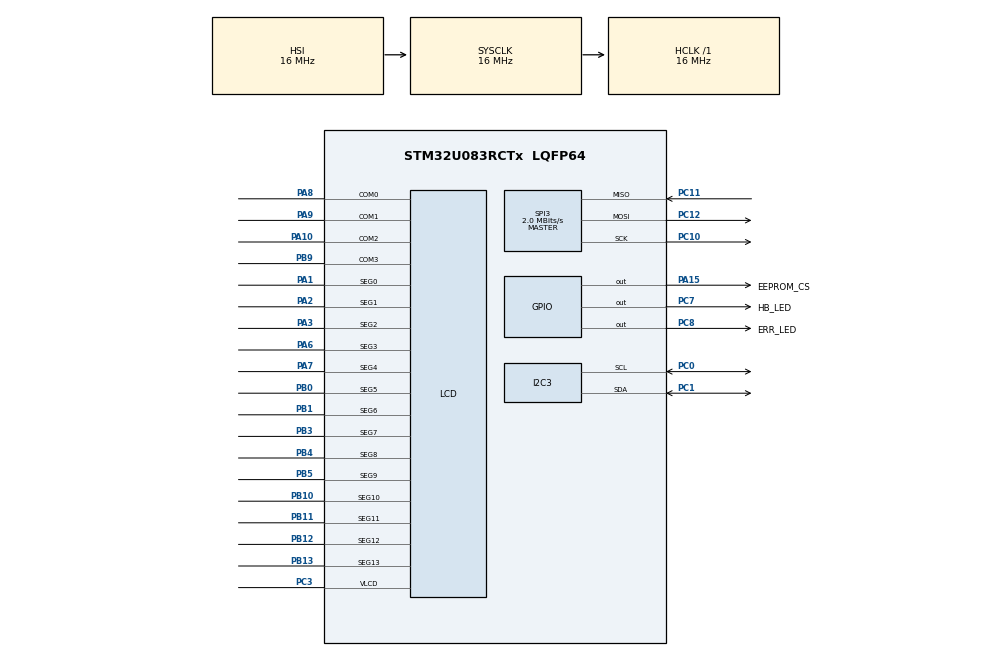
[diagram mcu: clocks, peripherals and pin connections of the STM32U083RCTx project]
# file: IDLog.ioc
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ADC1.Channel-0\#ChannelRegularConversion=ADC_CHANNEL_VBAT
ADC1.ClockPrescaler=ADC_CLOCK_ASYNC_DIV1
ADC1.ContinuousConvMode=ENABLE
ADC1.NbrOfConversionFlag=1
ADC1.Rank-0\#ChannelRegularConversion=1
ADC1.RankArg-0\#ChannelRegularConversion=ADC_REGULAR_RANK_1
ADC1.SamplingTime-0\#ChannelRegularConversion=ADC_SAMPLINGTIME_COMMON_1
ADC1.SamplingTimeCommon1=ADC_SAMPLETIME_79CYCLES_5
ADC1.SelectedChannel=ADC_CHANNEL_VBAT
ADC1.master=1
I2C3.Timing=0x00303D5B
LCD.Contrast=LCD_CONTRASTLEVEL_7
LCD.Divider=LCD_DIVIDER_31
LCD.Prescaler=LCD_PRESCALER_2
LCD.PulseOnDuration=LCD_PULSEONDURATION_5
Mcu.Family=STM32U0
Mcu.Name=STM32U083RCTx
Mcu.Package=LQFP64
NVIC.PriorityGroup=NVIC_PRIORITYGROUP_2
NVIC.TIM16_IRQn=true\:0\:0\:false\:false\:true\:true\:true\:true
PA1.Mode=SEG0
PA1.Signal=LCD_SEG0
PA10.Mode=1/4 Duty Cycle
PA10.Signal=LCD_COM2
PA15.GPIO_Label=EEPROM_CS
PA15.Signal=GPIO_Output
PA2.Mode=SEG1
PA2.Signal=LCD_SEG1
PA3.Mode=SEG2
PA3.Signal=LCD_SEG2
PA6.Mode=SEG3
PA6.Signal=LCD_SEG3
PA7.Mode=SEG4
PA7.Signal=LCD_SEG4
PA8.Mode=1/4 Duty Cycle
PA8.Signal=LCD_COM0
PA9.Mode=1/4 Duty Cycle
PA9.Signal=LCD_COM1
PB0.Mode=SEG5
PB0.Signal=LCD_SEG5
PB1.Mode=SEG6
PB1.Signal=LCD_SEG6
PB10.Mode=SEG10
PB10.Signal=LCD_SEG10
PB11.Mode=SEG11
PB11.Signal=LCD_SEG11
PB12.Mode=SEG12
PB12.Signal=LCD_SEG12
PB13.Mode=SEG13
PB13.Signal=LCD_SEG13
PB3.Mode=SEG7
PB3.Signal=LCD_SEG7
PB4.Mode=SEG8
PB4.Signal=LCD_SEG8
PB5.Mode=SEG9
PB5.Signal=LCD_SEG9
PB9.Mode=1/4 Duty Cycle
PB9.Signal=LCD_COM3
PC0.Mode=I2C
PC0.Signal=I2C3_SCL
PC1.Mode=I2C
PC1.Signal=I2C3_SDA
PC10.Mode=Full_Duplex_Master
PC10.Signal=SPI3_SCK
PC11.Mode=Full_Duplex_Master
PC11.Signal=SPI3_MISO
PC12.Mode=Full_Duplex_Master
PC12.Signal=SPI3_MOSI
PC3.Mode=1/4 Duty Cycle
PC3.Signal=LCD_VLCD
PC7.GPIO_Label=HB_LED
PC7.Signal=GPIO_Output
PC8.GPIO_Label=ERR_LED
PC8.Signal=GPIO_Output
ProjectManager.HeapSize=0x200
ProjectManager.StackSize=0x400
ProjectManager.TargetToolchain=STM32CubeIDE
RCC.AHBFreq_Value=16000000
RCC.CortexFreq_Value=16000000
RCC.HCLKFreq_Value=16000000
RCC.HSE_VALUE=4000000
RCC.HSI48_VALUE=48000000
RCC.HSI_VALUE=16000000
RCC.LSE_VALUE=32768
RCC.MSI_VALUE=4000000
RCC.SYSCLKFreq_VALUE=16000000
RCC.VCOOutputFreq_Value=64000000
RTC.Year=25
SPI3.BaudRatePrescaler=SPI_BAUDRATEPRESCALER_8
SPI3.CalculateBaudRate=2.0 MBits/s
SPI3.DataSize=SPI_DATASIZE_8BIT
SPI3.Direction=SPI_DIRECTION_2LINES
SPI3.Mode=SPI_MODE_MASTER
SPI3.VirtualType=VM_MASTER
TIM16.AutoReloadPreload=TIM_AUTORELOAD_PRELOAD_ENABLE
TIM16.Period=1000
TIM16.Prescaler=15
VP_ADC1_Vbat_Input.Mode=IN-Vbat
VP_PWR_VS_SECSignals.Mode=Security/Privilege
VP_RTC_VS_RTC_Activate.Mode=RTC_Enabled
VP_RTC_VS_RTC_Calendar.Mode=RTC_Calendar
VP_TIM16_VS_ClockSourceINT.Mode=Enable_Timer
board=custom

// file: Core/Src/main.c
/* USER CODE BEGIN Header */
/**
  ******************************************************************************
  * @file           : main.c
  * @brief          : Main program body
  ******************************************************************************
  * @attention
  *
  * Copyright (c) 2025 STMicroelectronics.
  * All rights reserved.
  *
  * This software is licensed under terms that can be found in the LICENSE file
  * in the root directory of this software component.
  * If no LICENSE file comes with this software, it is provided AS-IS.
  *
  ******************************************************************************
  */
/* USER CODE END Header */
#include "main.h"

/* USER CODE BEGIN Includes */
#include "HardwareConfig.h"
/* USER CODE END Includes */

ADC_HandleTypeDef hadc1;

I2C_HandleTypeDef hi2c3;

LCD_HandleTypeDef hlcd;

RTC_HandleTypeDef hrtc;

SPI_HandleTypeDef hspi3;

TIM_HandleTypeDef htim16;

void SystemClock_Config(void);
static void MX_GPIO_Init(void);
static void MX_I2C3_Init(void);
static void MX_SPI3_Init(void);
static void MX_ADC1_Init(void);
static void MX_TIM16_Init(void);
static void MX_LCD_Init(void);
static void MX_RTC_Init(void);

int main(void)
{

  /* MCU Configuration--------------------------------------------------------*/

  /* Reset of all peripherals, Initializes the Flash interface and the Systick. */
  HAL_Init();

  /* Configure the system clock */
  SystemClock_Config();

  /* Initialize all configured peripherals */
  MX_GPIO_Init();
  MX_I2C3_Init();
  MX_SPI3_Init();
  MX_ADC1_Init();
  MX_TIM16_Init();
  MX_LCD_Init();
  MX_RTC_Init();
  /* USER CODE BEGIN 2 */
  MainAppInit();
  /* USER CODE END 2 */

  /* Infinite loop */
  while (1)
  {

    /* USER CODE BEGIN 3 */
	  MainAppWhileFunction();
  }
  /* USER CODE END 3 */
}

void SystemClock_Config(void)
{
  RCC_OscInitTypeDef RCC_OscInitStruct = {0};
  RCC_ClkInitTypeDef RCC_ClkInitStruct = {0};

  /** Configure the main internal regulator output voltage
  */
  HAL_PWREx_ControlVoltageScaling(PWR_REGULATOR_VOLTAGE_SCALE2);

  /** Initializes the RCC Oscillators according to the specified parameters
  * in the RCC_OscInitTypeDef structure.
  */
  RCC_OscInitStruct.OscillatorType = RCC_OSCILLATORTYPE_HSI|RCC_OSCILLATORTYPE_LSI;
  RCC_OscInitStruct.HSIState = RCC_HSI_ON;
  RCC_OscInitStruct.HSICalibrationValue = RCC_HSICALIBRATION_DEFAULT;
  RCC_OscInitStruct.LSIState = RCC_LSI_ON;
  RCC_OscInitStruct.PLL.PLLState = RCC_PLL_NONE;
  if (HAL_RCC_OscConfig(&RCC_OscInitStruct) != HAL_OK)
  {
    Error_Handler();
  }

  /** Initializes the CPU, AHB and APB buses clocks
  */
  RCC_ClkInitStruct.ClockType = RCC_CLOCKTYPE_HCLK|RCC_CLOCKTYPE_SYSCLK
                              |RCC_CLOCKTYPE_PCLK1;
  RCC_ClkInitStruct.SYSCLKSource = RCC_SYSCLKSOURCE_HSI;
  RCC_ClkInitStruct.AHBCLKDivider = RCC_SYSCLK_DIV1;
  RCC_ClkInitStruct.APB1CLKDivider = RCC_HCLK_DIV1;

  if (HAL_RCC_ClockConfig(&RCC_ClkInitStruct, FLASH_LATENCY_1) != HAL_OK)
  {
    Error_Handler();
  }
}

static void MX_ADC1_Init(void)
{

  ADC_ChannelConfTypeDef sConfig = {0};

  /** Configure the global features of the ADC (Clock, Resolution, Data Alignment and number of conversion)
  */
  hadc1.Instance = ADC1;
  hadc1.Init.ClockPrescaler = ADC_CLOCK_ASYNC_DIV1;
  hadc1.Init.Resolution = ADC_RESOLUTION_12B;
  hadc1.Init.DataAlign = ADC_DATAALIGN_RIGHT;
  hadc1.Init.ScanConvMode = ADC_SCAN_DISABLE;
  hadc1.Init.EOCSelection = ADC_EOC_SINGLE_CONV;
  hadc1.Init.LowPowerAutoWait = DISABLE;
  hadc1.Init.LowPowerAutoPowerOff = DISABLE;
  hadc1.Init.ContinuousConvMode = ENABLE;
  hadc1.Init.NbrOfConversion = 1;
  hadc1.Init.ExternalTrigConv = ADC_SOFTWARE_START;
  hadc1.Init.ExternalTrigConvEdge = ADC_EXTERNALTRIGCONVEDGE_NONE;
  hadc1.Init.DMAContinuousRequests = DISABLE;
  hadc1.Init.Overrun = ADC_OVR_DATA_PRESERVED;
  hadc1.Init.SamplingTimeCommon1 = ADC_SAMPLETIME_79CYCLES_5;
  hadc1.Init.SamplingTimeCommon2 = ADC_SAMPLETIME_1CYCLE_5;
  hadc1.Init.OversamplingMode = DISABLE;
  hadc1.Init.TriggerFrequencyMode = ADC_TRIGGER_FREQ_HIGH;
  if (HAL_ADC_Init(&hadc1) != HAL_OK)
  {
    Error_Handler();
  }

  /** Configure Regular Channel
  */
  sConfig.Channel = ADC_CHANNEL_VBAT;
  sConfig.Rank = ADC_REGULAR_RANK_1;
  sConfig.SamplingTime = ADC_SAMPLINGTIME_COMMON_1;
  if (HAL_ADC_ConfigChannel(&hadc1, &sConfig) != HAL_OK)
  {
    Error_Handler();
  }

}

static void MX_I2C3_Init(void)
{

  hi2c3.Instance = I2C3;
  hi2c3.Init.Timing = 0x00303D5B;
  hi2c3.Init.OwnAddress1 = 0;
  hi2c3.Init.AddressingMode = I2C_ADDRESSINGMODE_7BIT;
  hi2c3.Init.DualAddressMode = I2C_DUALADDRESS_DISABLE;
  hi2c3.Init.OwnAddress2 = 0;
  hi2c3.Init.OwnAddress2Masks = I2C_OA2_NOMASK;
  hi2c3.Init.GeneralCallMode = I2C_GENERALCALL_DISABLE;
  hi2c3.Init.NoStretchMode = I2C_NOSTRETCH_DISABLE;
  if (HAL_I2C_Init(&hi2c3) != HAL_OK)
  {
    Error_Handler();
  }

  /** Configure Analogue filter
  */
  if (HAL_I2CEx_ConfigAnalogFilter(&hi2c3, I2C_ANALOGFILTER_ENABLE) != HAL_OK)
  {
    Error_Handler();
  }

  /** Configure Digital filter
  */
  if (HAL_I2CEx_ConfigDigitalFilter(&hi2c3, 0) != HAL_OK)
  {
    Error_Handler();
  }

}

static void MX_LCD_Init(void)
{

  hlcd.Instance = LCD;
  hlcd.Init.Prescaler = LCD_PRESCALER_2;
  hlcd.Init.Divider = LCD_DIVIDER_31;
  hlcd.Init.Duty = LCD_DUTY_1_4;
  hlcd.Init.Bias = LCD_BIAS_1_4;
  hlcd.Init.VoltageSource = LCD_VOLTAGESOURCE_INTERNAL;
  hlcd.Init.Contrast = LCD_CONTRASTLEVEL_7;
  hlcd.Init.DeadTime = LCD_DEADTIME_0;
  hlcd.Init.PulseOnDuration = LCD_PULSEONDURATION_5;
  hlcd.Init.BlinkMode = LCD_BLINKMODE_OFF;
  hlcd.Init.BlinkFrequency = LCD_BLINKFREQUENCY_DIV8;
  hlcd.Init.MuxSegment = LCD_MUXSEGMENT_DISABLE;
  if (HAL_LCD_Init(&hlcd) != HAL_OK)
  {
    Error_Handler();
  }

}

static void MX_RTC_Init(void)
{

  RTC_TimeTypeDef sTime = {0};
  RTC_DateTypeDef sDate = {0};

  /** Initialize RTC Only
  */
  hrtc.Instance = RTC;
  hrtc.Init.HourFormat = RTC_HOURFORMAT_24;
  hrtc.Init.AsynchPrediv = 127;
  hrtc.Init.SynchPrediv = 255;
  hrtc.Init.OutPut = RTC_OUTPUT_DISABLE;
  hrtc.Init.OutPutRemap = RTC_OUTPUT_REMAP_NONE;
  hrtc.Init.OutPutPolarity = RTC_OUTPUT_POLARITY_HIGH;
  hrtc.Init.OutPutType = RTC_OUTPUT_TYPE_OPENDRAIN;
  hrtc.Init.OutPutPullUp = RTC_OUTPUT_PULLUP_NONE;
  hrtc.Init.BinMode = RTC_BINARY_NONE;
  if (HAL_RTC_Init(&hrtc) != HAL_OK)
  {
    Error_Handler();
  }

  /** Initialize RTC and set the Time and Date
  */
  sTime.Hours = 0x0;
  sTime.Minutes = 0x0;
  sTime.Seconds = 0x0;
  sTime.DayLightSaving = RTC_DAYLIGHTSAVING_NONE;
  sTime.StoreOperation = RTC_STOREOPERATION_RESET;
  if (HAL_RTC_SetTime(&hrtc, &sTime, RTC_FORMAT_BCD) != HAL_OK)
  {
    Error_Handler();
  }
  sDate.WeekDay = RTC_WEEKDAY_MONDAY;
  sDate.Month = RTC_MONTH_JANUARY;
  sDate.Date = 0x1;
  sDate.Year = 0x25;

  if (HAL_RTC_SetDate(&hrtc, &sDate, RTC_FORMAT_BCD) != HAL_OK)
  {
    Error_Handler();
  }

}

static void MX_SPI3_Init(void)
{

  /* SPI3 parameter configuration*/
  hspi3.Instance = SPI3;
  hspi3.Init.Mode = SPI_MODE_MASTER;
  hspi3.Init.Direction = SPI_DIRECTION_2LINES;
  hspi3.Init.DataSize = SPI_DATASIZE_8BIT;
  hspi3.Init.CLKPolarity = SPI_POLARITY_LOW;
  hspi3.Init.CLKPhase = SPI_PHASE_1EDGE;
  hspi3.Init.NSS = SPI_NSS_SOFT;
  hspi3.Init.BaudRatePrescaler = SPI_BAUDRATEPRESCALER_8;
  hspi3.Init.FirstBit = SPI_FIRSTBIT_MSB;
  hspi3.Init.TIMode = SPI_TIMODE_DISABLE;
  hspi3.Init.CRCCalculation = SPI_CRCCALCULATION_DISABLE;
  hspi3.Init.CRCPolynomial = 7;
  hspi3.Init.CRCLength = SPI_CRC_LENGTH_DATASIZE;
  hspi3.Init.NSSPMode = SPI_NSS_PULSE_ENABLE;
  if (HAL_SPI_Init(&hspi3) != HAL_OK)
  {
    Error_Handler();
  }

}

static void MX_TIM16_Init(void)
{

  htim16.Instance = TIM16;
  htim16.Init.Prescaler = 15;
  htim16.Init.CounterMode = TIM_COUNTERMODE_UP;
  htim16.Init.Period = 1000;
  htim16.Init.ClockDivision = TIM_CLOCKDIVISION_DIV1;
  htim16.Init.RepetitionCounter = 0;
  htim16.Init.AutoReloadPreload = TIM_AUTORELOAD_PRELOAD_ENABLE;
  if (HAL_TIM_Base_Init(&htim16) != HAL_OK)
  {
    Error_Handler();
  }

}

static void MX_GPIO_Init(void)
{
  GPIO_InitTypeDef GPIO_InitStruct = {0};

  /* GPIO Ports Clock Enable */
  __HAL_RCC_GPIOC_CLK_ENABLE();
  __HAL_RCC_GPIOA_CLK_ENABLE();
  __HAL_RCC_GPIOB_CLK_ENABLE();

  /*Configure GPIO pin Output Level */
  HAL_GPIO_WritePin(GPIOC, HB_LED_Pin|ERR_LED_Pin, GPIO_PIN_RESET);

  /*Configure GPIO pin Output Level */
  HAL_GPIO_WritePin(EEPROM_CS_GPIO_Port, EEPROM_CS_Pin, GPIO_PIN_RESET);

  /*Configure GPIO pins : HB_LED_Pin ERR_LED_Pin */
  GPIO_InitStruct.Pin = HB_LED_Pin|ERR_LED_Pin;
  GPIO_InitStruct.Mode = GPIO_MODE_OUTPUT_PP;
  GPIO_InitStruct.Pull = GPIO_NOPULL;
  GPIO_InitStruct.Speed = GPIO_SPEED_FREQ_LOW;
  HAL_GPIO_Init(GPIOC, &GPIO_InitStruct);

  /*Configure GPIO pin : EEPROM_CS_Pin */
  GPIO_InitStruct.Pin = EEPROM_CS_Pin;
  GPIO_InitStruct.Mode = GPIO_MODE_OUTPUT_PP;
  GPIO_InitStruct.Pull = GPIO_NOPULL;
  GPIO_InitStruct.Speed = GPIO_SPEED_FREQ_LOW;
  HAL_GPIO_Init(EEPROM_CS_GPIO_Port, &GPIO_InitStruct);

}

void Error_Handler(void)
{
  __disable_irq();
  while (1)
  {
  }
}
